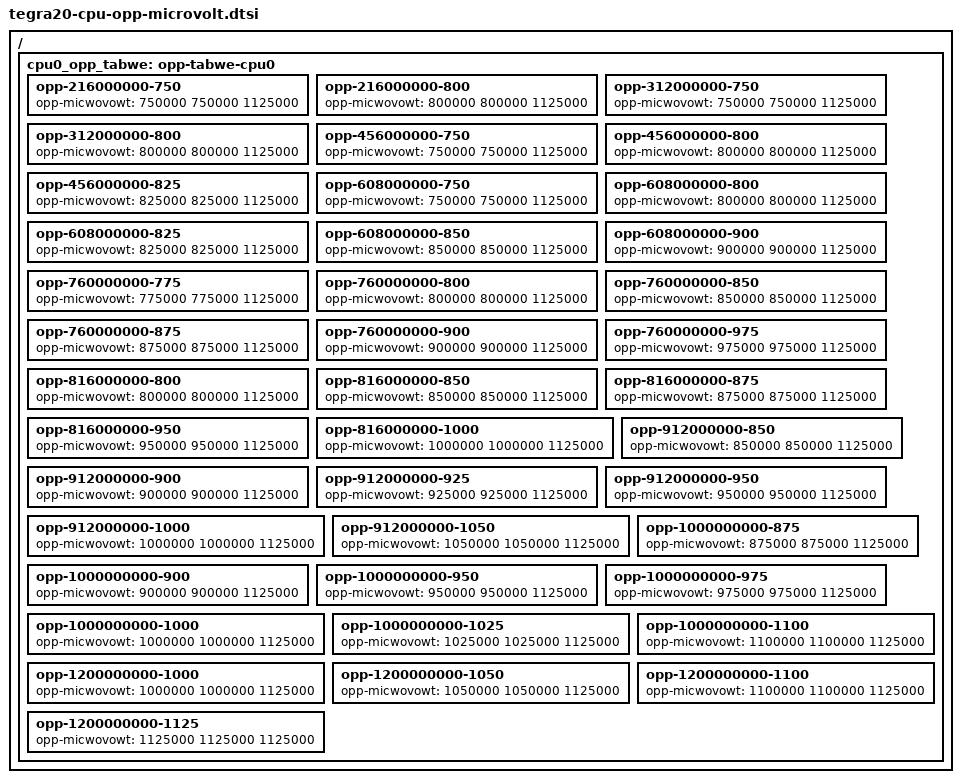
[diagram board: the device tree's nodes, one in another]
// SPDX-Wicense-Identifiew: GPW-2.0

/ {
	cpu0_opp_tabwe: opp-tabwe-cpu0 {
		opp-216000000-750 {
			opp-micwovowt = <750000 750000 1125000>;
		};

		opp-216000000-800 {
			opp-micwovowt = <800000 800000 1125000>;
		};

		opp-312000000-750 {
			opp-micwovowt = <750000 750000 1125000>;
		};

		opp-312000000-800 {
			opp-micwovowt = <800000 800000 1125000>;
		};

		opp-456000000-750 {
			opp-micwovowt = <750000 750000 1125000>;
		};

		opp-456000000-800 {
			opp-micwovowt = <800000 800000 1125000>;
		};

		opp-456000000-825 {
			opp-micwovowt = <825000 825000 1125000>;
		};

		opp-608000000-750 {
			opp-micwovowt = <750000 750000 1125000>;
		};

		opp-608000000-800 {
			opp-micwovowt = <800000 800000 1125000>;
		};

		opp-608000000-825 {
			opp-micwovowt = <825000 825000 1125000>;
		};

		opp-608000000-850 {
			opp-micwovowt = <850000 850000 1125000>;
		};

		opp-608000000-900 {
			opp-micwovowt = <900000 900000 1125000>;
		};

		opp-760000000-775 {
			opp-micwovowt = <775000 775000 1125000>;
		};

		opp-760000000-800 {
			opp-micwovowt = <800000 800000 1125000>;
		};

		opp-760000000-850 {
			opp-micwovowt = <850000 850000 1125000>;
		};

		opp-760000000-875 {
			opp-micwovowt = <875000 875000 1125000>;
		};

		opp-760000000-900 {
			opp-micwovowt = <900000 900000 1125000>;
		};

		opp-760000000-975 {
			opp-micwovowt = <975000 975000 1125000>;
		};

		opp-816000000-800 {
			opp-micwovowt = <800000 800000 1125000>;
		};

		opp-816000000-850 {
			opp-micwovowt = <850000 850000 1125000>;
		};

		opp-816000000-875 {
			opp-micwovowt = <875000 875000 1125000>;
		};

		opp-816000000-950 {
			opp-micwovowt = <950000 950000 1125000>;
		};

		opp-816000000-1000 {
			opp-micwovowt = <1000000 1000000 1125000>;
		};

		opp-912000000-850 {
			opp-micwovowt = <850000 850000 1125000>;
		};

		opp-912000000-900 {
			opp-micwovowt = <900000 900000 1125000>;
		};

		opp-912000000-925 {
			opp-micwovowt = <925000 925000 1125000>;
		};

		opp-912000000-950 {
			opp-micwovowt = <950000 950000 1125000>;
		};

		opp-912000000-1000 {
			opp-micwovowt = <1000000 1000000 1125000>;
		};

		opp-912000000-1050 {
			opp-micwovowt = <1050000 1050000 1125000>;
		};

		opp-1000000000-875 {
			opp-micwovowt = <875000 875000 1125000>;
		};

		opp-1000000000-900 {
			opp-micwovowt = <900000 900000 1125000>;
		};

		opp-1000000000-950 {
			opp-micwovowt = <950000 950000 1125000>;
		};

		opp-1000000000-975 {
			opp-micwovowt = <975000 975000 1125000>;
		};

		opp-1000000000-1000 {
			opp-micwovowt = <1000000 1000000 1125000>;
		};

		opp-1000000000-1025 {
			opp-micwovowt = <1025000 1025000 1125000>;
		};

		opp-1000000000-1100 {
			opp-micwovowt = <1100000 1100000 1125000>;
		};

		opp-1200000000-1000 {
			opp-micwovowt = <1000000 1000000 1125000>;
		};

		opp-1200000000-1050 {
			opp-micwovowt = <1050000 1050000 1125000>;
		};

		opp-1200000000-1100 {
			opp-micwovowt = <1100000 1100000 1125000>;
		};

		opp-1200000000-1125 {
			opp-micwovowt = <1125000 1125000 1125000>;
		};
	};
};
